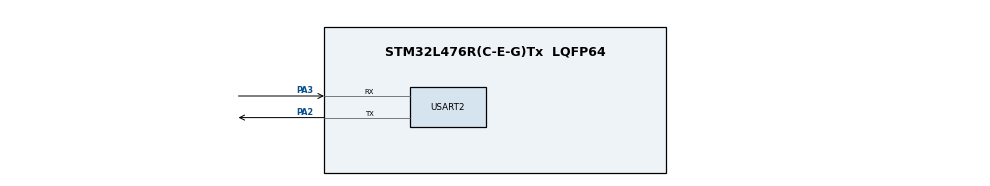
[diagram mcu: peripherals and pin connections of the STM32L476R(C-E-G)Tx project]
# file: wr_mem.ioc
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Mcu.Family=STM32L4
Mcu.Name=STM32L476R(C-E-G)Tx
Mcu.Package=LQFP64
NVIC.PriorityGroup=NVIC_PRIORITYGROUP_4
PA2.Mode=Asynchronous
PA2.Signal=USART2_TX
PA3.Mode=Asynchronous
PA3.Signal=USART2_RX
ProjectManager.HeapSize=0x200
ProjectManager.StackSize=0x400
ProjectManager.TargetToolchain=Makefile
RCC.HSE_VALUE=8000000
RCC.HSI_VALUE=16000000
RCC.LSE_VALUE=32768
RCC.MSI_VALUE=4000000
RCC.VCOOutputFreq_Value=32000000
USART2.VirtualMode-Asynchronous=VM_ASYNC
board=custom

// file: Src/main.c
/* USER CODE BEGIN Header */
/*

 /$$      /$$ /$$$$$$$        /$$      /$$ /$$$$$$$$ /$$      /$$
| $$  /$ | $$| $$__  $$      | $$$    /$$$| $$_____/| $$$    /$$$
| $$ /$$$| $$| $$  \ $$      | $$$$  /$$$$| $$      | $$$$  /$$$$
| $$/$$ $$ $$| $$$$$$$/      | $$ $$/$$ $$| $$$$$   | $$ $$/$$ $$
| $$$$_  $$$$| $$__  $$      | $$  $$$| $$| $$__/   | $$  $$$| $$
| $$$/ \  $$$| $$  \ $$      | $$\  $ | $$| $$      | $$\  $ | $$
| $$/   \  $$| $$  | $$      | $$ \/  | $$| $$$$$$$$| $$ \/  | $$
|__/     \__/|__/  |__/      |__/     |__/|________/|__/     |__/
*/
/* Used for LoRa Firmware Update Over the Air project. Embedded system course University of Trento.
This application is able to write bytes into its own memory following these steps:
1) UNLOCK flash
2) ERASE memory
3) WRITE on memory
4) LOCK flash
/**
  ******************************************************************************
  * @file           : main.c
  * @brief          : Main program body
  ******************************************************************************
  * @attention
  *
  * <h2><center>&copy; Copyright (c) 2020 STMicroelectronics.
  * All rights reserved.</center></h2>
  *
  * This software component is licensed by ST under BSD 3-Clause license,
  * the "License"; You may not use this file except in compliance with the
  * License. You may obtain a copy of the License at:
  *                        opensource.org/licenses/BSD-3-Clause
  *
  ******************************************************************************
  */
/* USER CODE END Header */

#include "main.h"

/* USER CODE BEGIN Includes */
#include <stdio.h>
#include <stdlib.h>
#include <string.h>
/* USER CODE END Includes */

UART_HandleTypeDef huart2;

void SystemClock_Config(void);
static void MX_GPIO_Init(void);
static void MX_USART2_UART_Init(void);
/* USER CODE BEGIN PFP */
static void FLASH_Program_DoubleWord(uint32_t Address, uint64_t Data); // Writing double-word on flash
/* USER CODE END PFP */

int main(void)
{

  /* MCU Configuration--------------------------------------------------------*/

  /* Reset of all peripherals, Initializes the Flash interface and the Systick. */
  HAL_Init();

  /* Configure the system clock */
  SystemClock_Config();

  /* Initialize all configured peripherals */
  MX_GPIO_Init();
  MX_USART2_UART_Init();
  /* USER CODE BEGIN 2 */
  char txt[256]; // Debug buffer
  HAL_StatusTypeDef status;

  // UNLOCK flash memory
  status = HAL_FLASH_Unlock();
  sprintf(txt, "Unlock: %d\r\n", status);
  HAL_UART_Transmit(&huart2, (uint8_t *)txt, strlen(txt), 1000);

  // ERASE all pages of FLASH_BANK_1
  for (size_t i = 0; i < 256; i++)
  {
    FLASH_PageErase(i, FLASH_BANK_1);
    status = FLASH_WaitForLastOperation(1000); // Wait until operation ends
    sprintf(txt, "Wait: %d\r\n", status);
    HAL_UART_Transmit(&huart2, (uint8_t *)txt, strlen(txt), 1000);
  }

  uint32_t aaaa = 0x080A00A0;       // ADDRESS
  uint64_t dd = 0x0F1F2F3F4F5F6F7F; // DATA
  // STORE DATA in flash memory
  FLASH_Program_DoubleWord(aaaa, dd);

  // LOCK flash memory
  status = HAL_FLASH_Lock();
  sprintf(txt, "Lock: %d\r\n", status);
  HAL_UART_Transmit(&huart2, (uint8_t *)txt, strlen(txt), 1000);

  /* USER CODE END 2 */

  /* Infinite loop */
  while (1)
  {

  }
}

void SystemClock_Config(void)
{
  RCC_OscInitTypeDef RCC_OscInitStruct = {0};
  RCC_ClkInitTypeDef RCC_ClkInitStruct = {0};
  RCC_PeriphCLKInitTypeDef PeriphClkInit = {0};

  /** Initializes the CPU, AHB and APB busses clocks
  */
  RCC_OscInitStruct.OscillatorType = RCC_OSCILLATORTYPE_MSI;
  RCC_OscInitStruct.MSIState = RCC_MSI_ON;
  RCC_OscInitStruct.MSICalibrationValue = 0;
  RCC_OscInitStruct.MSIClockRange = RCC_MSIRANGE_6;
  RCC_OscInitStruct.PLL.PLLState = RCC_PLL_NONE;
  if (HAL_RCC_OscConfig(&RCC_OscInitStruct) != HAL_OK)
  {
    Error_Handler();
  }
  /** Initializes the CPU, AHB and APB busses clocks
  */
  RCC_ClkInitStruct.ClockType = RCC_CLOCKTYPE_HCLK | RCC_CLOCKTYPE_SYSCLK | RCC_CLOCKTYPE_PCLK1 | RCC_CLOCKTYPE_PCLK2;
  RCC_ClkInitStruct.SYSCLKSource = RCC_SYSCLKSOURCE_MSI;
  RCC_ClkInitStruct.AHBCLKDivider = RCC_SYSCLK_DIV1;
  RCC_ClkInitStruct.APB1CLKDivider = RCC_HCLK_DIV1;
  RCC_ClkInitStruct.APB2CLKDivider = RCC_HCLK_DIV1;

  if (HAL_RCC_ClockConfig(&RCC_ClkInitStruct, FLASH_LATENCY_0) != HAL_OK)
  {
    Error_Handler();
  }
  PeriphClkInit.PeriphClockSelection = RCC_PERIPHCLK_USART2;
  PeriphClkInit.Usart2ClockSelection = RCC_USART2CLKSOURCE_PCLK1;
  if (HAL_RCCEx_PeriphCLKConfig(&PeriphClkInit) != HAL_OK)
  {
    Error_Handler();
  }
  /** Configure the main internal regulator output voltage
  */
  if (HAL_PWREx_ControlVoltageScaling(PWR_REGULATOR_VOLTAGE_SCALE1) != HAL_OK)
  {
    Error_Handler();
  }
}

static void MX_USART2_UART_Init(void)
{

  huart2.Instance = USART2;
  huart2.Init.BaudRate = 115200;
  huart2.Init.WordLength = UART_WORDLENGTH_8B;
  huart2.Init.StopBits = UART_STOPBITS_1;
  huart2.Init.Parity = UART_PARITY_NONE;
  huart2.Init.Mode = UART_MODE_TX_RX;
  huart2.Init.HwFlowCtl = UART_HWCONTROL_NONE;
  huart2.Init.OverSampling = UART_OVERSAMPLING_16;
  huart2.Init.OneBitSampling = UART_ONE_BIT_SAMPLE_DISABLE;
  huart2.AdvancedInit.AdvFeatureInit = UART_ADVFEATURE_NO_INIT;
  if (HAL_UART_Init(&huart2) != HAL_OK)
  {
    Error_Handler();
  }
}

static void MX_GPIO_Init(void)
{

  /* GPIO Ports Clock Enable */
  __HAL_RCC_GPIOA_CLK_ENABLE();
}

/* USER CODE BEGIN 4 */
/**
  * @brief  Program double-word (64-bit) at a specified address.
  * @param  Address specifies the address to be programmed.
  * @param  Data specifies the data to be programmed.
  * @retval None
  */
static void FLASH_Program_DoubleWord(uint32_t Address, uint64_t Data) // Writing double-word on flash
{
  assert_param(IS_FLASH_PROGRAM_ADDRESS(Address)); // Check the parameters
  SET_BIT(FLASH->CR, FLASH_CR_PG);                 // Set PG bit
  *(__IO uint32_t *)Address = (uint32_t)Data;      // Program first word
  /* Barrier to ensure programming is performed in 2 steps, in right order
    (independently of compiler optimization behavior) */
  __ISB();
  *(__IO uint32_t *)(Address + 4U) = (uint32_t)(Data >> 32); // Program second word
}

/* USER CODE END 4 */

void Error_Handler(void)
{
}

/************************ (C) COPYRIGHT STMicroelectronics *****END OF FILE****/
